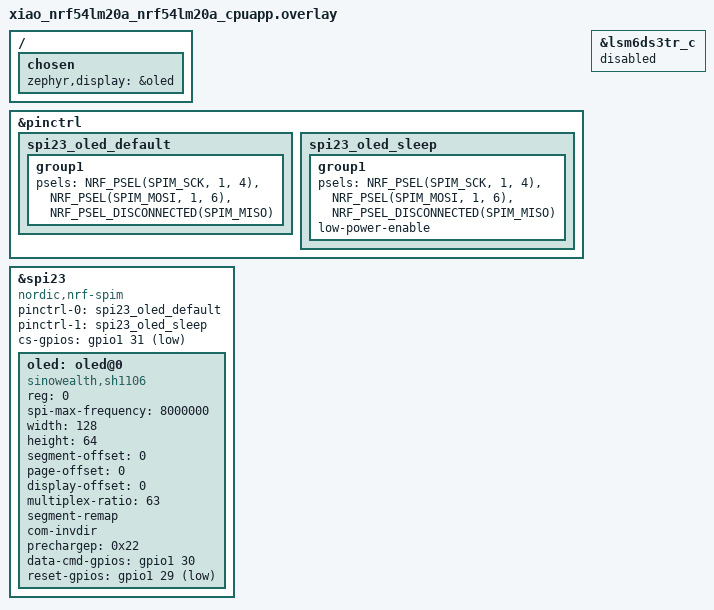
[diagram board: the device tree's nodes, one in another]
/*
 * SH1106 SPI OLED demo overlay for XIAO nRF54LM20A
 *
 * Recommended wiring:
 *   OLED SCK -> D8  (P1.04)
 *   OLED SDA -> D10 (P1.06, SPI MOSI)
 *   OLED RST -> D3  (P1.29)
 *   OLED DC  -> D2  (P1.30)
 *   OLED CS  -> D1  (P1.31)
 */

/ {
	chosen {
		zephyr,display = &oled;
	};
};

&pinctrl {
	spi23_oled_default: spi23_oled_default {
		group1 {
			psels = <NRF_PSEL(SPIM_SCK, 1, 4)>,
				<NRF_PSEL(SPIM_MOSI, 1, 6)>,
				<NRF_PSEL_DISCONNECTED(SPIM_MISO)>;
		};
	};

	spi23_oled_sleep: spi23_oled_sleep {
		group1 {
			psels = <NRF_PSEL(SPIM_SCK, 1, 4)>,
				<NRF_PSEL(SPIM_MOSI, 1, 6)>,
				<NRF_PSEL_DISCONNECTED(SPIM_MISO)>;
			low-power-enable;
		};
	};
};

&spi23 {
	compatible = "nordic,nrf-spim";
	status = "okay";
	pinctrl-0 = <&spi23_oled_default>;
	pinctrl-1 = <&spi23_oled_sleep>;
	pinctrl-names = "default", "sleep";
	cs-gpios = <&gpio1 31 GPIO_ACTIVE_LOW>;

	oled: oled@0 {
		compatible = "sinowealth,sh1106";
		reg = <0>;
		spi-max-frequency = <8000000>;
		width = <128>;
		height = <64>;
		segment-offset = <0>;
		page-offset = <0>;
		display-offset = <0>;
		multiplex-ratio = <63>;
		segment-remap;
		com-invdir;
		prechargep = <0x22>;
		data-cmd-gpios = <&gpio1 30 GPIO_ACTIVE_HIGH>;
		reset-gpios = <&gpio1 29 GPIO_ACTIVE_LOW>;
		status = "okay";
	};
};

&lsm6ds3tr_c {
	status = "disabled";
};
